# STM32H745xx_CM7 register map
File version: 1.0
Registers are 32-bit, read-write, reset 0x0 unless marked. A register's access mark holds for its fields unless they carry their own. Offsets are from the block's base; [hi:lo] are bit positions.

## CEC — Consumer Electronics Control
Base 0x40006C00
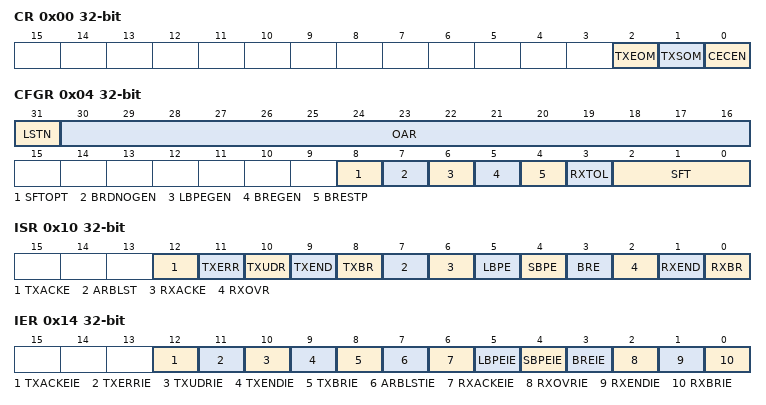
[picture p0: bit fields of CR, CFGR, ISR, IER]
0x00 CR — CEC control register
  [2] TXEOM — CEC Tx End Of Message
  [1] TXSOM — CEC Tx Start Of Message
  [0] CECEN — CEC Enable
0x04 CFGR — CEC configuration register
  [31] LSTN — CEC Listen mode
  [30:16] OAR — CEC Own Address
  [8] SFTOPT — CEC Signal Free Time optional
  [7] BRDNOGEN — CEC Broadcast No error generation
  [6] LBPEGEN — CEC Long Bit Period Error generation
  [5] BREGEN — CEC Bit Rising Error generation
  [4] BRESTP — CEC Rx Stop
  [3] RXTOL — CEC Tolerance
  [2:0] SFT — CEC Signal Free Time
0x08 TXDR — CEC Tx data register
  [7:0] TXD — CEC Tx Data
0x0C RXDR — CEC Rx Data Register
  [7:0] RXD — CEC Rx Data
0x10 ISR — CEC Interrupt and Status Register
  [12] TXACKE — CEC Tx Missing Acknowledge
  [11] TXERR — CEC Tx-Error
  [10] TXUDR — CEC Tx-Buffer Underrun
  [9] TXEND — CEC End of Transmission
  [8] TXBR — CEC Tx Byte Request
  [7] ARBLST — CEC Arbitration Lost
  [6] RXACKE — CEC Rx Missing Acknowledge
  [5] LBPE — CEC Rx Long Bit period Error
  [4] SBPE — CEC Rx Short Bit period Error
  [3] BRE — CEC Rx Bit Rising Error
  [2] RXOVR — CEC Rx-Overrun
  [1] RXEND — CEC End Of Reception
  [0] RXBR — CEC Rx-Byte Received
0x14 IER — CEC interrupt enable register
  [12] TXACKEIE — CEC Tx Missing Acknowledge IT Enable
  [11] TXERRIE — CEC Tx-Error IT Enable
  [10] TXUDRIE — CEC Tx-Buffer Underrun IT Enable
  [9] TXENDIE — CEC End of Transmission IT Enable
  [8] TXBRIE — CEC Tx Byte Request IT Enable
  [7] ARBLSTIE — CEC Arbitration Lost IT Enable
  [6] RXACKEIE — CEC Rx Missing Acknowledge IT Enable
  [5] LBPEIE — CEC Rx Long Bit period Error IT Enable
  [4] SBPEIE — CEC Rx Short Bit period Error IT Enable
  [3] BREIE — CEC Rx Bit Rising Error IT Enable
  [2] RXOVRIE — CEC Rx-Overrun IT Enable
  [1] RXENDIE — CEC End Of Reception IT Enable
  [0] RXBRIE — CEC Rx-Byte Received IT Enable

## CRS — Clock Recovery System
Base 0x40008400
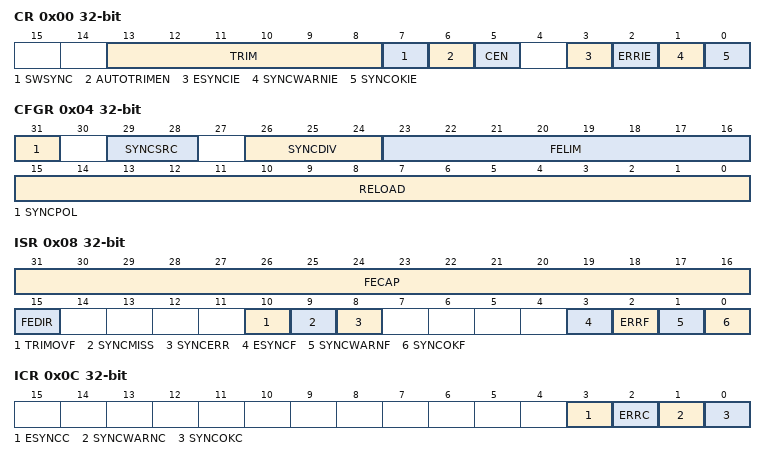
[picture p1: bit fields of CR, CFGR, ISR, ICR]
0x00 CR — CRS ccontrol register
  [13:8] TRIM — HSI48 oscillator smooth trimming
  [7] SWSYNC — Generate software SYNC event
  [6] AUTOTRIMEN — Automatic trimming enable
  [5] CEN — Frequency error counter enable
  [3] ESYNCIE — Expected SYNC interrupt enable
  [2] ERRIE — SYNC error or trimming error interrupt enable
  [1] SYNCWARNIE — SYNC warning interrupt enable
  [0] SYNCOKIE — SYNC event OK interrupt enable
0x04 CFGR — CRS configuration register
  [31] SYNCPOL — SYNC polarity selection
    0=RISING (Synchro Active on rising edge (default)); 1=FALLING (Synchro Active on falling edge)
  [29:28] SYNCSRC — SYNC signal source selection
    0=GPIO (Synchro Signal source GPIO); 1=LSE (Synchro Signal source LSE); 2=USB (Synchro Signal source USB SOF (default))
  [26:24] SYNCDIV — SYNC divider
    0=DIV_1 (Synchro Signal not divided (default)); 1=DIV_2 (Synchro Signal divided by 2); 2=DIV_4 (Synchro Signal divided by 4); 3=DIV_8 (Synchro Signal divided by 8); 4=DIV_16 (Synchro Signal divided by 16); 5=DIV_32 (Synchro Signal divided by 32); 6=DIV_64 (Synchro Signal divided by 64); 7=DIV_128 (Synchro Signal divided by 128)
  [23:16] FELIM — Frequency error limit
  [15:0] RELOAD — Counter reload value
0x08 ISR — CRS interrupt and status register
  [31:16] FECAP — Frequency error capture
  [15] FEDIR — Frequency error direction
    0=UP (Upcounting direction, the actual frequency is above the target); 1=DOWN (Downcounting direction, the actual frequency is below the target)
  [10] TRIMOVF — Trimming overflow or underflow
  [9] SYNCMISS — SYNC missed
  [8] SYNCERR — SYNC error
  [3] ESYNCF — Expected SYNC flag
  [2] ERRF — Error flag
  [1] SYNCWARNF — SYNC warning flag
  [0] SYNCOKF — SYNC event OK flag
0x0C ICR — CRS interrupt flag clear register
  [3] ESYNCC — Expected SYNC clear flag
  [2] ERRC — Error clear flag
  [1] SYNCWARNC — SYNC warning clear flag
  [0] SYNCOKC — SYNC event OK clear flag
